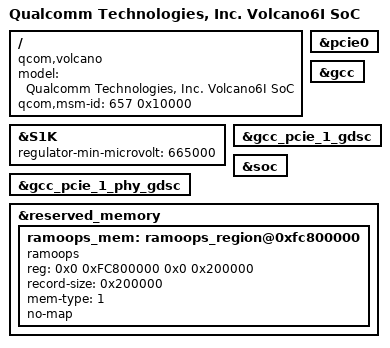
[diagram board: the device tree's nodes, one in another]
#include "volcano6.dtsi"

&S1K {
			regulator-min-microvolt = <665000>;
};

/ {
	model = "Qualcomm Technologies, Inc. Volcano6I SoC";
	compatible = "qcom,volcano";
	qcom,msm-id = <657 0x10000>;
};

&pcie0 {
	status = "ok";
};

&gcc {
	/delete-property/ protected-clocks;
};

&gcc_pcie_1_gdsc {
	status = "ok";
};

&gcc_pcie_1_phy_gdsc {
	status = "ok";
};

&soc {
	/delete-node/ ramoops_region;
};

&reserved_memory {
	#address-cells = <2>;
	#size-cells = <2>;
	ranges;

	ramoops_mem: ramoops_region@0xfc800000 {
		compatible = "ramoops";
		reg = <0x0 0xFC800000 0x0 0x200000>;
		record-size = <0x200000>;
		mem-type = <1>;
		no-map;
	};
};
